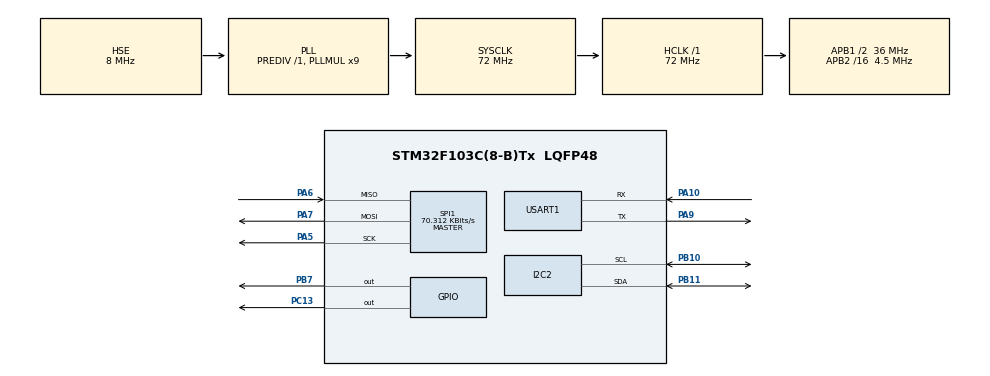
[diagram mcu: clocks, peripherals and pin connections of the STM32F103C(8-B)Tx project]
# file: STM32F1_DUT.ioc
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Mcu.Family=STM32F1
Mcu.Name=STM32F103C(8-B)Tx
Mcu.Package=LQFP48
NVIC.PriorityGroup=NVIC_PRIORITYGROUP_4
NVIC.TIM1_UP_IRQn=true\:15\:0\:false\:false\:true\:false\:true\:true
NVIC.TimeBase=TIM1_UP_IRQn
NVIC.TimeBaseIP=TIM1
NVIC.USART1_IRQn=true\:6\:0\:true\:false\:true\:true\:true\:true
PA10.Mode=Asynchronous
PA10.Signal=USART1_RX
PA13.Mode=Serial_Wire
PA13.Signal=SYS_JTMS-SWDIO
PA14.Mode=Serial_Wire
PA14.Signal=SYS_JTCK-SWCLK
PA5.Mode=Full_Duplex_Master
PA5.Signal=SPI1_SCK
PA6.GPIO_PuPd=GPIO_NOPULL
PA6.Mode=Full_Duplex_Master
PA6.Signal=SPI1_MISO
PA7.Mode=Full_Duplex_Master
PA7.Signal=SPI1_MOSI
PA9.Mode=Asynchronous
PA9.Signal=USART1_TX
PB10.Mode=I2C
PB10.Signal=I2C2_SCL
PB11.Mode=I2C
PB11.Signal=I2C2_SDA
PB7.Signal=GPIO_Output
PC13-TAMPER-RTC.Signal=GPIO_Output
PD0-OSC_IN.Mode=HSE-External-Oscillator
PD0-OSC_IN.Signal=RCC_OSC_IN
PD1-OSC_OUT.Mode=HSE-External-Oscillator
PD1-OSC_OUT.Signal=RCC_OSC_OUT
ProjectManager.HeapSize=0x200
ProjectManager.StackSize=0x400
ProjectManager.TargetToolchain=STM32CubeIDE
RCC.AHBFreq_Value=72000000
RCC.APB1CLKDivider=RCC_HCLK_DIV2
RCC.APB1Freq_Value=36000000
RCC.APB1TimFreq_Value=72000000
RCC.APB2CLKDivider=RCC_HCLK_DIV16
RCC.APB2Freq_Value=4500000
RCC.APB2TimFreq_Value=9000000
RCC.HCLKFreq_Value=72000000
RCC.PLLMUL=RCC_PLL_MUL9
RCC.PLLSourceVirtual=RCC_PLLSOURCE_HSE
RCC.SYSCLKFreq_VALUE=72000000
RCC.SYSCLKSource=RCC_SYSCLKSOURCE_PLLCLK
RCC.USBFreq_Value=72000000
SPI1.BaudRatePrescaler=SPI_BAUDRATEPRESCALER_64
SPI1.CLKPhase=SPI_PHASE_2EDGE
SPI1.CalculateBaudRate=70.312 KBits/s
SPI1.Direction=SPI_DIRECTION_2LINES
SPI1.Mode=SPI_MODE_MASTER
SPI1.VirtualType=VM_MASTER
USART1.VirtualMode=VM_ASYNC
VP_SYS_VS_tim1.Mode=TIM1
board=custom

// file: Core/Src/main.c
/* USER CODE BEGIN Header */
/**
  ******************************************************************************
  * @file           : main.c
  * @brief          : Main program body
  ******************************************************************************
  * @attention
  *
  * Copyright (c) 2026 STMicroelectronics.
  * All rights reserved.
  *
  * This software is licensed under terms that can be found in the LICENSE file
  * in the root directory of this software component.
  * If no LICENSE file comes with this software, it is provided AS-IS.
  *
  ******************************************************************************
  */
/* USER CODE END Header */
#include "main.h"

/* USER CODE BEGIN Includes */
#include "FreeRTOS.h"
#include "task.h"
#include "command.h"
#include "w25q_driver.h"
/* USER CODE END Includes */

I2C_HandleTypeDef hi2c2;

void SystemClock_Config(void);
static void MX_GPIO_Init(void);
static void MX_I2C2_Init(void);
static void MX_SPI1_Init(void);
static void MX_USART1_UART_Init(void);
/* USER CODE BEGIN PFP */
static void toggle_led(void *pvParameters);
/* USER CODE END PFP */

int main(void)
{

  /* MCU Configuration--------------------------------------------------------*/

  /* Reset of all peripherals, Initializes the Flash interface and the Systick. */
  HAL_Init();

  /* Configure the system clock */
  SystemClock_Config();

  /* Initialize all configured peripherals */
  MX_GPIO_Init();
  MX_I2C2_Init();
  MX_SPI1_Init();
  MX_USART1_UART_Init();
  /* USER CODE BEGIN 2 */
	W25Q_Init(&W25Q);
	CommandLine_Init(DUT_UART_CONSOLE_HANDLE);

	xTaskCreate(CommandLine_Task, "DUT Console", configMINIMAL_STACK_SIZE * 4, NULL, 2, NULL);
	xTaskCreate(toggle_led, "toggle_led", configMINIMAL_STACK_SIZE, NULL, 1, NULL);
	vTaskStartScheduler();
  /* USER CODE END 2 */

  /* Infinite loop */
  while (1)
  {

  }
}

void SystemClock_Config(void)
{
  RCC_OscInitTypeDef RCC_OscInitStruct = {0};
  RCC_ClkInitTypeDef RCC_ClkInitStruct = {0};

  /** Initializes the RCC Oscillators according to the specified parameters
  * in the RCC_OscInitTypeDef structure.
  */
  RCC_OscInitStruct.OscillatorType = RCC_OSCILLATORTYPE_HSE;
  RCC_OscInitStruct.HSEState = RCC_HSE_ON;
  RCC_OscInitStruct.HSEPredivValue = RCC_HSE_PREDIV_DIV1;
  RCC_OscInitStruct.HSIState = RCC_HSI_ON;
  RCC_OscInitStruct.PLL.PLLState = RCC_PLL_ON;
  RCC_OscInitStruct.PLL.PLLSource = RCC_PLLSOURCE_HSE;
  RCC_OscInitStruct.PLL.PLLMUL = RCC_PLL_MUL9;
  if (HAL_RCC_OscConfig(&RCC_OscInitStruct) != HAL_OK)
  {
    Error_Handler();
  }

  /** Initializes the CPU, AHB and APB buses clocks
  */
  RCC_ClkInitStruct.ClockType = RCC_CLOCKTYPE_HCLK|RCC_CLOCKTYPE_SYSCLK
                              |RCC_CLOCKTYPE_PCLK1|RCC_CLOCKTYPE_PCLK2;
  RCC_ClkInitStruct.SYSCLKSource = RCC_SYSCLKSOURCE_PLLCLK;
  RCC_ClkInitStruct.AHBCLKDivider = RCC_SYSCLK_DIV1;
  RCC_ClkInitStruct.APB1CLKDivider = RCC_HCLK_DIV2;
  RCC_ClkInitStruct.APB2CLKDivider = RCC_HCLK_DIV16;

  if (HAL_RCC_ClockConfig(&RCC_ClkInitStruct, FLASH_LATENCY_2) != HAL_OK)
  {
    Error_Handler();
  }
}

static void MX_I2C2_Init(void)
{

  hi2c2.Instance = I2C2;
  hi2c2.Init.ClockSpeed = 100000;
  hi2c2.Init.DutyCycle = I2C_DUTYCYCLE_2;
  hi2c2.Init.OwnAddress1 = 0;
  hi2c2.Init.AddressingMode = I2C_ADDRESSINGMODE_7BIT;
  hi2c2.Init.DualAddressMode = I2C_DUALADDRESS_DISABLE;
  hi2c2.Init.OwnAddress2 = 0;
  hi2c2.Init.GeneralCallMode = I2C_GENERALCALL_DISABLE;
  hi2c2.Init.NoStretchMode = I2C_NOSTRETCH_DISABLE;
  if (HAL_I2C_Init(&hi2c2) != HAL_OK)
  {
    Error_Handler();
  }

}

static void MX_SPI1_Init(void)
{

  LL_SPI_InitTypeDef SPI_InitStruct = {0};

  LL_GPIO_InitTypeDef GPIO_InitStruct = {0};

  /* Peripheral clock enable */
  LL_APB2_GRP1_EnableClock(LL_APB2_GRP1_PERIPH_SPI1);

  LL_APB2_GRP1_EnableClock(LL_APB2_GRP1_PERIPH_GPIOA);
  /**SPI1 GPIO Configuration
  PA5   ------> SPI1_SCK
  PA6   ------> SPI1_MISO
  PA7   ------> SPI1_MOSI
  */
  GPIO_InitStruct.Pin = LL_GPIO_PIN_5|LL_GPIO_PIN_7;
  GPIO_InitStruct.Mode = LL_GPIO_MODE_ALTERNATE;
  GPIO_InitStruct.Speed = LL_GPIO_SPEED_FREQ_HIGH;
  GPIO_InitStruct.OutputType = LL_GPIO_OUTPUT_PUSHPULL;
  LL_GPIO_Init(GPIOA, &GPIO_InitStruct);

  GPIO_InitStruct.Pin = LL_GPIO_PIN_6;
  GPIO_InitStruct.Mode = LL_GPIO_MODE_FLOATING;
  LL_GPIO_Init(GPIOA, &GPIO_InitStruct);

  /* SPI1 parameter configuration*/
  SPI_InitStruct.TransferDirection = LL_SPI_FULL_DUPLEX;
  SPI_InitStruct.Mode = LL_SPI_MODE_MASTER;
  SPI_InitStruct.DataWidth = LL_SPI_DATAWIDTH_8BIT;
  SPI_InitStruct.ClockPolarity = LL_SPI_POLARITY_LOW;
  SPI_InitStruct.ClockPhase = LL_SPI_PHASE_2EDGE;
  SPI_InitStruct.NSS = LL_SPI_NSS_SOFT;
  SPI_InitStruct.BaudRate = LL_SPI_BAUDRATEPRESCALER_DIV64;
  SPI_InitStruct.BitOrder = LL_SPI_MSB_FIRST;
  SPI_InitStruct.CRCCalculation = LL_SPI_CRCCALCULATION_DISABLE;
  SPI_InitStruct.CRCPoly = 10;
  LL_SPI_Init(SPI1, &SPI_InitStruct);
  /* USER CODE BEGIN SPI1_Init 2 */
  LL_SPI_Enable(SPI1);
  /* USER CODE END SPI1_Init 2 */

}

static void MX_USART1_UART_Init(void)
{

  LL_USART_InitTypeDef USART_InitStruct = {0};

  LL_GPIO_InitTypeDef GPIO_InitStruct = {0};

  /* Peripheral clock enable */
  LL_APB2_GRP1_EnableClock(LL_APB2_GRP1_PERIPH_USART1);

  LL_APB2_GRP1_EnableClock(LL_APB2_GRP1_PERIPH_GPIOA);
  /**USART1 GPIO Configuration
  PA9   ------> USART1_TX
  PA10   ------> USART1_RX
  */
  GPIO_InitStruct.Pin = LL_GPIO_PIN_9;
  GPIO_InitStruct.Mode = LL_GPIO_MODE_ALTERNATE;
  GPIO_InitStruct.Speed = LL_GPIO_SPEED_FREQ_HIGH;
  GPIO_InitStruct.OutputType = LL_GPIO_OUTPUT_PUSHPULL;
  LL_GPIO_Init(GPIOA, &GPIO_InitStruct);

  GPIO_InitStruct.Pin = LL_GPIO_PIN_10;
  GPIO_InitStruct.Mode = LL_GPIO_MODE_FLOATING;
  LL_GPIO_Init(GPIOA, &GPIO_InitStruct);

  /* USART1 interrupt Init */
  NVIC_SetPriority(USART1_IRQn, NVIC_EncodePriority(NVIC_GetPriorityGrouping(),6, 0));
  NVIC_EnableIRQ(USART1_IRQn);

  USART_InitStruct.BaudRate = 115200;
  USART_InitStruct.DataWidth = LL_USART_DATAWIDTH_8B;
  USART_InitStruct.StopBits = LL_USART_STOPBITS_1;
  USART_InitStruct.Parity = LL_USART_PARITY_NONE;
  USART_InitStruct.TransferDirection = LL_USART_DIRECTION_TX_RX;
  USART_InitStruct.HardwareFlowControl = LL_USART_HWCONTROL_NONE;
  USART_InitStruct.OverSampling = LL_USART_OVERSAMPLING_16;
  LL_USART_Init(USART1, &USART_InitStruct);
  LL_USART_ConfigAsyncMode(USART1);
  LL_USART_Enable(USART1);

}

static void MX_GPIO_Init(void)
{
  LL_GPIO_InitTypeDef GPIO_InitStruct = {0};

  /* GPIO Ports Clock Enable */
  LL_APB2_GRP1_EnableClock(LL_APB2_GRP1_PERIPH_GPIOC);
  LL_APB2_GRP1_EnableClock(LL_APB2_GRP1_PERIPH_GPIOD);
  LL_APB2_GRP1_EnableClock(LL_APB2_GRP1_PERIPH_GPIOA);
  LL_APB2_GRP1_EnableClock(LL_APB2_GRP1_PERIPH_GPIOB);

  /**/
  LL_GPIO_ResetOutputPin(GPIOC, LL_GPIO_PIN_13);

  /**/
  LL_GPIO_ResetOutputPin(GPIOB, LL_GPIO_PIN_7);

  /**/
  GPIO_InitStruct.Pin = LL_GPIO_PIN_13;
  GPIO_InitStruct.Mode = LL_GPIO_MODE_OUTPUT;
  GPIO_InitStruct.Speed = LL_GPIO_SPEED_FREQ_LOW;
  GPIO_InitStruct.OutputType = LL_GPIO_OUTPUT_PUSHPULL;
  LL_GPIO_Init(GPIOC, &GPIO_InitStruct);

  /**/
  GPIO_InitStruct.Pin = LL_GPIO_PIN_7;
  GPIO_InitStruct.Mode = LL_GPIO_MODE_OUTPUT;
  GPIO_InitStruct.Speed = LL_GPIO_SPEED_FREQ_LOW;
  GPIO_InitStruct.OutputType = LL_GPIO_OUTPUT_PUSHPULL;
  LL_GPIO_Init(GPIOB, &GPIO_InitStruct);

}

/* USER CODE BEGIN 4 */
static void toggle_led(void *pvParameters)
{
	while (1) {
		LL_GPIO_TogglePin(GPIOC, LL_GPIO_PIN_13);
		vTaskDelay(pdMS_TO_TICKS(500));
	}
}
/* USER CODE END 4 */

void HAL_TIM_PeriodElapsedCallback(TIM_HandleTypeDef *htim)
{
  if (htim->Instance == TIM1) {
    HAL_IncTick();
  }
}

void Error_Handler(void)
{
  __disable_irq();
  while (1)
  {
  }
}
